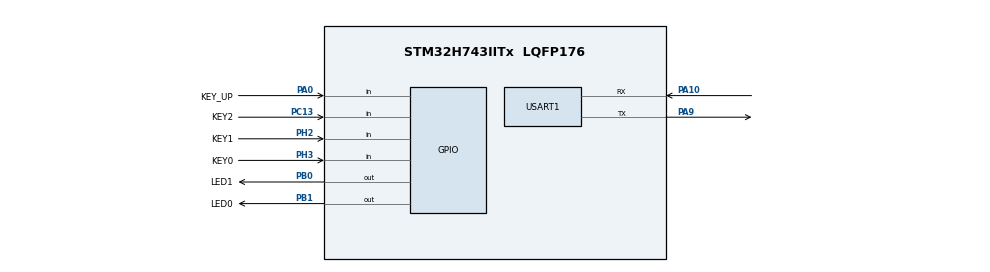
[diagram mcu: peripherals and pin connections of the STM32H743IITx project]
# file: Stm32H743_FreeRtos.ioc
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CORTEX_M7.CPU_DCache=Enabled
CORTEX_M7.CPU_ICache=Enabled
FREERTOS.Tasks01=MainTask,1,128,StartMainTask,Default,NULL,Dynamic,NULL,NULL;myTask02,0,128,StartTask02,Default,NULL,Dynamic,NULL,NULL;myTask03,0,128,StartTask03,Default,NULL,Dynamic,NULL,NULL;myTask04,0,128,StartTask04,Default,NULL,Dynamic,NULL,NULL;myTask05,0,128,StartTask05,Default,NULL,Dynamic,NULL,NULL;myTask06,0,128,StartTask06,Default,NULL,Dynamic,NULL,NULL;myTask07,0,128,StartTask07,Default,NULL,Dynamic,NULL,NULL;myTask08,0,128,StartTask08,Default,NULL,Dynamic,NULL,NULL;myTask09,0,128,StartTask09,Default,NULL,Dynamic,NULL,NULL;myTask10,0,128,StartTask10,Default,NULL,Dynamic,NULL,NULL;myTask11,0,128,StartTask11,Default,NULL,Dynamic,NULL,NULL;myTask12,0,128,StartTask12,Default,NULL,Dynamic,NULL,NULL
FREERTOS.configENABLE_FPU=1
Mcu.Family=STM32H7
Mcu.Name=STM32H743IITx
Mcu.Package=LQFP176
NVIC.PriorityGroup=NVIC_PRIORITYGROUP_4
NVIC.TIM7_IRQn=true\:15\:0\:false\:false\:true\:false\:false\:true
NVIC.TimeBase=TIM7_IRQn
NVIC.TimeBaseIP=TIM7
NVIC.USART1_IRQn=true\:5\:0\:false\:false\:true\:true\:true\:true
PA0.GPIO_Label=KEY_UP
PA0.GPIO_PuPd=GPIO_PULLDOWN
PA0.Signal=GPIO_Input
PA10.GPIO_PuPd=GPIO_PULLUP
PA10.GPIO_Speed=GPIO_SPEED_FREQ_VERY_HIGH
PA10.Mode=Asynchronous
PA10.Signal=USART1_RX
PA9.GPIO_PuPd=GPIO_PULLUP
PA9.GPIO_Speed=GPIO_SPEED_FREQ_VERY_HIGH
PA9.Mode=Asynchronous
PA9.Signal=USART1_TX
PB0.GPIO_Label=LED1
PB0.GPIO_ModeDefaultOutputPP=GPIO_MODE_OUTPUT_PP
PB0.GPIO_PuPd=GPIO_PULLUP
PB0.GPIO_Speed=GPIO_SPEED_FREQ_VERY_HIGH
PB0.PinState=GPIO_PIN_RESET
PB0.Signal=GPIO_Output
PB1.GPIO_Label=LED0
PB1.GPIO_ModeDefaultOutputPP=GPIO_MODE_OUTPUT_PP
PB1.GPIO_PuPd=GPIO_PULLUP
PB1.GPIO_Speed=GPIO_SPEED_FREQ_VERY_HIGH
PB1.PinState=GPIO_PIN_RESET
PB1.Signal=GPIO_Output
PC13.GPIO_Label=KEY2
PC13.GPIO_PuPd=GPIO_PULLUP
PC13.Signal=GPIO_Input
PC14-OSC32_IN\ (OSC32_IN).Mode=LSE-External-Oscillator
PC14-OSC32_IN\ (OSC32_IN).Signal=RCC_OSC32_IN
PC15-OSC32_OUT\ (OSC32_OUT).Mode=LSE-External-Oscillator
PC15-OSC32_OUT\ (OSC32_OUT).Signal=RCC_OSC32_OUT
PH0-OSC_IN\ (PH0).Mode=HSE-External-Oscillator
PH0-OSC_IN\ (PH0).Signal=RCC_OSC_IN
PH1-OSC_OUT\ (PH1).Mode=HSE-External-Oscillator
PH1-OSC_OUT\ (PH1).Signal=RCC_OSC_OUT
PH2.GPIO_Label=KEY1
PH2.GPIO_PuPd=GPIO_PULLUP
PH2.Signal=GPIO_Input
PH3.GPIO_Label=KEY0
PH3.GPIO_PuPd=GPIO_PULLUP
PH3.Signal=GPIO_Input
ProjectManager.HeapSize=0x200
ProjectManager.StackSize=0x400
ProjectManager.TargetToolchain=MDK-ARM V5
RCC.ADCFreq_Value=129000000
RCC.APB1Freq_Value=120000000
RCC.APB2Freq_Value=120000000
RCC.APB3Freq_Value=120000000
RCC.APB4Freq_Value=120000000
RCC.CortexFreq_Value=480000000
RCC.D1PPRE=RCC_APB3_DIV2
RCC.D2PPRE1=RCC_APB1_DIV2
RCC.D2PPRE2=RCC_APB2_DIV2
RCC.D3PPRE=RCC_APB4_DIV2
RCC.DIVM1=4
RCC.DIVN1=60
RCC.HCLKFreq_Value=240000000
RCC.HPRE=RCC_HCLK_DIV2
RCC.PLL2FRACN=0
RCC.PLL3FRACN=0
RCC.PLLFRACN=0
RCC.PWR_Regulator_Voltage_Scale=PWR_REGULATOR_VOLTAGE_SCALE0
RCC.SYSCLKFreq_VALUE=480000000
RCC.SYSCLKSource=RCC_SYSCLKSOURCE_PLLCLK
RCC.USBFreq_Value=480000000
USART1.VirtualMode-Asynchronous=VM_ASYNC
VP_FREERTOS_VS_CMSIS_V1.Mode=CMSIS_V1
VP_SYS_VS_tim7.Mode=TIM7
board=custom

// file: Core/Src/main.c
/* USER CODE BEGIN Header */
/**
  ******************************************************************************
  * @file           : main.c
  * @brief          : Main program body
  ******************************************************************************
  * @attention
  *
  * Copyright (c) 2022 STMicroelectronics.
  * All rights reserved.
  *
  * This software is licensed under terms that can be found in the LICENSE file
  * in the root directory of this software component.
  * If no LICENSE file comes with this software, it is provided AS-IS.
  *
  ******************************************************************************
  */
/* USER CODE END Header */
#include "main.h"
#include "cmsis_os.h"
#include "usart.h"
#include "gpio.h"

void SystemClock_Config(void);
void MX_FREERTOS_Init(void);

int main(void)
{

  /* Enable I-Cache---------------------------------------------------------*/
  SCB_EnableICache();

  /* Enable D-Cache---------------------------------------------------------*/
  SCB_EnableDCache();

  /* MCU Configuration--------------------------------------------------------*/

  /* Reset of all peripherals, Initializes the Flash interface and the Systick. */
  HAL_Init();

  /* Configure the system clock */
  SystemClock_Config();

  /* Initialize all configured peripherals */
  MX_GPIO_Init();
  MX_USART1_UART_Init();

  /* Call init function for freertos objects (in freertos.c) */
  MX_FREERTOS_Init();
  /* Start scheduler */
  osKernelStart();

  /* We should never get here as control is now taken by the scheduler */
  /* Infinite loop */
  while (1)
  {

  }
}

void SystemClock_Config(void)
{
  RCC_OscInitTypeDef RCC_OscInitStruct = {0};
  RCC_ClkInitTypeDef RCC_ClkInitStruct = {0};

  /** Supply configuration update enable
  */
  HAL_PWREx_ConfigSupply(PWR_LDO_SUPPLY);
  /** Configure the main internal regulator output voltage
  */
  __HAL_PWR_VOLTAGESCALING_CONFIG(PWR_REGULATOR_VOLTAGE_SCALE0);

  while(!__HAL_PWR_GET_FLAG(PWR_FLAG_VOSRDY)) {}
  /** Initializes the RCC Oscillators according to the specified parameters
  * in the RCC_OscInitTypeDef structure.
  */
  RCC_OscInitStruct.OscillatorType = RCC_OSCILLATORTYPE_HSI;
  RCC_OscInitStruct.HSIState = RCC_HSI_DIV1;
  RCC_OscInitStruct.HSICalibrationValue = RCC_HSICALIBRATION_DEFAULT;
  RCC_OscInitStruct.PLL.PLLState = RCC_PLL_ON;
  RCC_OscInitStruct.PLL.PLLSource = RCC_PLLSOURCE_HSI;
  RCC_OscInitStruct.PLL.PLLM = 4;
  RCC_OscInitStruct.PLL.PLLN = 60;
  RCC_OscInitStruct.PLL.PLLP = 2;
  RCC_OscInitStruct.PLL.PLLQ = 2;
  RCC_OscInitStruct.PLL.PLLR = 2;
  RCC_OscInitStruct.PLL.PLLRGE = RCC_PLL1VCIRANGE_3;
  RCC_OscInitStruct.PLL.PLLVCOSEL = RCC_PLL1VCOWIDE;
  RCC_OscInitStruct.PLL.PLLFRACN = 0;
  if (HAL_RCC_OscConfig(&RCC_OscInitStruct) != HAL_OK)
  {
    Error_Handler();
  }
  /** Initializes the CPU, AHB and APB buses clocks
  */
  RCC_ClkInitStruct.ClockType = RCC_CLOCKTYPE_HCLK|RCC_CLOCKTYPE_SYSCLK
                              |RCC_CLOCKTYPE_PCLK1|RCC_CLOCKTYPE_PCLK2
                              |RCC_CLOCKTYPE_D3PCLK1|RCC_CLOCKTYPE_D1PCLK1;
  RCC_ClkInitStruct.SYSCLKSource = RCC_SYSCLKSOURCE_PLLCLK;
  RCC_ClkInitStruct.SYSCLKDivider = RCC_SYSCLK_DIV1;
  RCC_ClkInitStruct.AHBCLKDivider = RCC_HCLK_DIV2;
  RCC_ClkInitStruct.APB3CLKDivider = RCC_APB3_DIV2;
  RCC_ClkInitStruct.APB1CLKDivider = RCC_APB1_DIV2;
  RCC_ClkInitStruct.APB2CLKDivider = RCC_APB2_DIV2;
  RCC_ClkInitStruct.APB4CLKDivider = RCC_APB4_DIV2;

  if (HAL_RCC_ClockConfig(&RCC_ClkInitStruct, FLASH_LATENCY_4) != HAL_OK)
  {
    Error_Handler();
  }
}

void HAL_TIM_PeriodElapsedCallback(TIM_HandleTypeDef *htim)
{
  if (htim->Instance == TIM7) {
    HAL_IncTick();
  }
}

void Error_Handler(void)
{
  __disable_irq();
  while (1)
  {
  }
}

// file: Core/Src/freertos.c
/* USER CODE BEGIN Header */
/**
  ******************************************************************************
  * File Name          : freertos.c
  * Description        : Code for freertos applications
  ******************************************************************************
  * @attention
  *
  * Copyright (c) 2022 STMicroelectronics.
  * All rights reserved.
  *
  * This software is licensed under terms that can be found in the LICENSE file
  * in the root directory of this software component.
  * If no LICENSE file comes with this software, it is provided AS-IS.
  *
  ******************************************************************************
  */
/* USER CODE END Header */

#include "FreeRTOS.h"
#include "task.h"
#include "main.h"
#include "cmsis_os.h"

osThreadId MainTaskHandle;
osThreadId myTask02Handle;
osThreadId myTask03Handle;
osThreadId myTask04Handle;
osThreadId myTask05Handle;
osThreadId myTask06Handle;
osThreadId myTask07Handle;
osThreadId myTask08Handle;
osThreadId myTask09Handle;
osThreadId myTask10Handle;
osThreadId myTask11Handle;
osThreadId myTask12Handle;
extern void usartSend();

void StartMainTask(void const * argument);
void StartTask02(void const * argument);
void StartTask03(void const * argument);
void StartTask04(void const * argument);
void StartTask05(void const * argument);
void StartTask06(void const * argument);
void StartTask07(void const * argument);
void StartTask08(void const * argument);
void StartTask09(void const * argument);
void StartTask10(void const * argument);
void StartTask11(void const * argument);
void StartTask12(void const * argument);

void MX_FREERTOS_Init(void); /* (MISRA C 2004 rule 8.1) */

/* GetIdleTaskMemory prototype (linked to static allocation support) */
void vApplicationGetIdleTaskMemory( StaticTask_t **ppxIdleTaskTCBBuffer, StackType_t **ppxIdleTaskStackBuffer, uint32_t *pulIdleTaskStackSize );

/* USER CODE BEGIN GET_IDLE_TASK_MEMORY */
static StaticTask_t xIdleTaskTCBBuffer;
static StackType_t xIdleStack[configMINIMAL_STACK_SIZE];

void vApplicationGetIdleTaskMemory( StaticTask_t **ppxIdleTaskTCBBuffer, StackType_t **ppxIdleTaskStackBuffer, uint32_t *pulIdleTaskStackSize )
{
  *ppxIdleTaskTCBBuffer = &xIdleTaskTCBBuffer;
  *ppxIdleTaskStackBuffer = &xIdleStack[0];
  *pulIdleTaskStackSize = configMINIMAL_STACK_SIZE;
  /* place for user code */
}
/* USER CODE END GET_IDLE_TASK_MEMORY */

void MX_FREERTOS_Init(void) {

  /* Create the thread(s) */
  /* definition and creation of MainTask */
  osThreadDef(MainTask, StartMainTask, osPriorityAboveNormal, 0, 128);
  MainTaskHandle = osThreadCreate(osThread(MainTask), NULL);

  /* definition and creation of myTask02 */
  osThreadDef(myTask02, StartTask02, osPriorityNormal, 0, 128);
  myTask02Handle = osThreadCreate(osThread(myTask02), NULL);

  /* definition and creation of myTask03 */
  osThreadDef(myTask03, StartTask03, osPriorityNormal, 0, 128);
  myTask03Handle = osThreadCreate(osThread(myTask03), NULL);

  /* definition and creation of myTask04 */
  osThreadDef(myTask04, StartTask04, osPriorityNormal, 0, 128);
  myTask04Handle = osThreadCreate(osThread(myTask04), NULL);

  /* definition and creation of myTask05 */
  osThreadDef(myTask05, StartTask05, osPriorityNormal, 0, 128);
  myTask05Handle = osThreadCreate(osThread(myTask05), NULL);

  /* definition and creation of myTask06 */
  osThreadDef(myTask06, StartTask06, osPriorityNormal, 0, 128);
  myTask06Handle = osThreadCreate(osThread(myTask06), NULL);

  /* definition and creation of myTask07 */
  osThreadDef(myTask07, StartTask07, osPriorityNormal, 0, 128);
  myTask07Handle = osThreadCreate(osThread(myTask07), NULL);

  /* definition and creation of myTask08 */
  osThreadDef(myTask08, StartTask08, osPriorityNormal, 0, 128);
  myTask08Handle = osThreadCreate(osThread(myTask08), NULL);

  /* definition and creation of myTask09 */
  osThreadDef(myTask09, StartTask09, osPriorityNormal, 0, 128);
  myTask09Handle = osThreadCreate(osThread(myTask09), NULL);

  /* definition and creation of myTask10 */
  osThreadDef(myTask10, StartTask10, osPriorityNormal, 0, 128);
  myTask10Handle = osThreadCreate(osThread(myTask10), NULL);

  /* definition and creation of myTask11 */
  osThreadDef(myTask11, StartTask11, osPriorityNormal, 0, 128);
  myTask11Handle = osThreadCreate(osThread(myTask11), NULL);

  /* definition and creation of myTask12 */
  osThreadDef(myTask12, StartTask12, osPriorityNormal, 0, 128);
  myTask12Handle = osThreadCreate(osThread(myTask12), NULL);

}

void StartMainTask(void const * argument)
{
  for(;;)
  {
    osDelay(1);
  }
}

void StartTask02(void const * argument)
{
  /* USER CODE BEGIN StartTask02 */
  /* Infinite loop */
  for(;;)
  {
		usartSend();
    osDelay(1);
  }
  /* USER CODE END StartTask02 */
}

void StartTask03(void const * argument)
{
  for(;;)
  {
    osDelay(1);
  }
}

void StartTask04(void const * argument)
{
  for(;;)
  {
    osDelay(1);
  }
}

void StartTask05(void const * argument)
{
  for(;;)
  {
    osDelay(1);
  }
}

void StartTask06(void const * argument)
{
  for(;;)
  {
    osDelay(1);
  }
}

void StartTask07(void const * argument)
{
  for(;;)
  {
    osDelay(1);
  }
}

void StartTask08(void const * argument)
{
  for(;;)
  {
    osDelay(1);
  }
}

void StartTask09(void const * argument)
{
  for(;;)
  {
    osDelay(1);
  }
}

void StartTask10(void const * argument)
{
  for(;;)
  {
    osDelay(1);
  }
}

void StartTask11(void const * argument)
{
  for(;;)
  {
    osDelay(1);
  }
}

void StartTask12(void const * argument)
{
  for(;;)
  {
    osDelay(1);
  }
}
